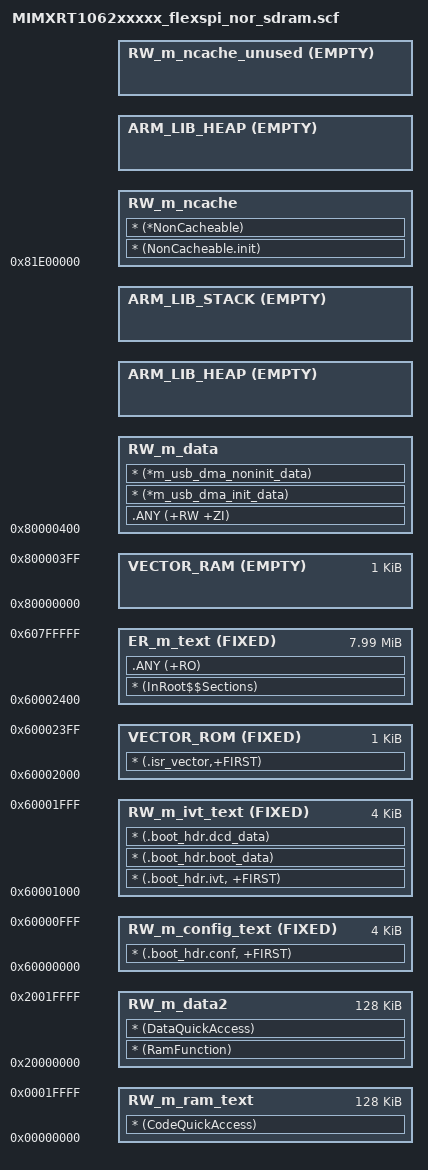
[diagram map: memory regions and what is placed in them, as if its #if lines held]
#!armclang --target=arm-arm-none-eabi -mcpu=cortex-m7 -E -x c
/*
** ###################################################################
**     Processors:          MIMXRT1062CVJ5A
**                          MIMXRT1062CVL5A
**                          MIMXRT1062DVJ6A
**                          MIMXRT1062DVL6A
**                          MIMXRT1062DVN6B
**                          MIMXRT1062XVN5B
**
**     Compiler:            Keil ARM C/C++ Compiler
**     Reference manual:    IMXRT1060RM Rev.3, 07/2021 | IMXRT106XSRM Rev.0
**     Version:             rev. 0.2, 2022-03-25
**     Build:               b220401
**
**     Abstract:
**         Linker file for the Keil ARM C/C++ Compiler
**
**     Copyright 2016 Freescale Semiconductor, Inc.
**     Copyright 2016-2022 NXP
**     All rights reserved.
**
**     SPDX-License-Identifier: BSD-3-Clause
**
**     http:                 www.nxp.com
**     mail:                 support@nxp.com
**
** ###################################################################
*/

#if (defined(__ram_vector_table__))
  #define __ram_vector_table_size__    0x00000400
#else
  #define __ram_vector_table_size__    0x00000000
#endif

#define m_flash_config_start           0x60000000
#define m_flash_config_size            0x00001000

#define m_ivt_start                    0x60001000
#define m_ivt_size                     0x00001000

#define m_interrupts_start             0x60002000
#define m_interrupts_size              0x00000400

#define m_text_start                   0x60002400
#define m_text_size                    0x007FDC00

#define m_qacode_start                 0x00000000
#define m_qacode_size                  0x00020000

#define m_interrupts_ram_start         0x80000000
#define m_interrupts_ram_size          __ram_vector_table_size__

#define m_data_start                   (m_interrupts_ram_start + m_interrupts_ram_size)
#define m_data_size                    (0x01E00000 - m_interrupts_ram_size)

#define m_ncache_start                 0x81E00000
#define m_ncache_size                  0x00200000

#define m_data2_start                  0x20000000
#define m_data2_size                   0x00020000

#define m_data3_start                  0x20200000
#define m_data3_size                   0x000C0000

/* Sizes */
#if (defined(__stack_size__))
  #define Stack_Size                   __stack_size__
#else
  #define Stack_Size                   0x0400
#endif

#if (defined(__heap_size__))
  #define Heap_Size                    __heap_size__
#else
  #define Heap_Size                    0x0400
#endif

#if defined(XIP_BOOT_HEADER_ENABLE) && (XIP_BOOT_HEADER_ENABLE == 1)
LR_m_text m_flash_config_start m_text_start+m_text_size-m_flash_config_start {   ; load region size_region
  RW_m_config_text m_flash_config_start FIXED m_flash_config_size { ; load address = execution address
    * (.boot_hdr.conf, +FIRST)
  }

  RW_m_ivt_text m_ivt_start FIXED m_ivt_size { ; load address = execution address
    * (.boot_hdr.ivt, +FIRST)
    * (.boot_hdr.boot_data)
    * (.boot_hdr.dcd_data)
  }
#else
LR_m_text m_interrupts_start m_text_start+m_text_size-m_interrupts_start {   ; load region size_region
#endif
  VECTOR_ROM m_interrupts_start FIXED m_interrupts_size { ; load address = execution address
    * (.isr_vector,+FIRST)
  }
  ER_m_text m_text_start FIXED m_text_size { ; load address = execution address
    * (InRoot$$Sections)
    .ANY (+RO)
  }
#if (defined(__ram_vector_table__))
  VECTOR_RAM m_interrupts_ram_start EMPTY m_interrupts_ram_size {
  }
#else
  VECTOR_RAM m_interrupts_start EMPTY 0 {
  }
#endif
  RW_m_data2 m_data2_start m_data2_size {
    * (RamFunction)
    * (DataQuickAccess)
  }
#if (defined(__heap_noncacheable__))
  RW_m_data m_data_start m_data_size-Stack_Size { ; RW data
#else
  RW_m_data m_data_start m_data_size-Stack_Size-Heap_Size { ; RW data
#endif
    .ANY (+RW +ZI)
    * (*m_usb_dma_init_data)
    * (*m_usb_dma_noninit_data)
  }
#if (!defined(__heap_noncacheable__))
  ARM_LIB_HEAP +0 EMPTY Heap_Size {    ; Heap region growing up
  }
#endif
  ARM_LIB_STACK m_data_start+m_data_size EMPTY -Stack_Size { ; Stack region growing down
  }
  RW_m_ram_text m_qacode_start m_qacode_size { ;
    * (CodeQuickAccess)
  }
#if (defined(__heap_noncacheable__))
  RW_m_ncache m_ncache_start m_ncache_size - Heap_Size { ; ncache RW data
#else
  RW_m_ncache m_ncache_start m_ncache_size { ; ncache RW data
#endif
    * (NonCacheable.init)
    * (*NonCacheable)
  }
#if (defined(__heap_noncacheable__))
  ARM_LIB_HEAP +0 EMPTY Heap_Size {    ; Heap region growing up
  }
  RW_m_ncache_unused +0 EMPTY m_ncache_size-ImageLength(RW_m_ncache)-Heap_Size { ; Empty region added for MPU configuration
#else
  RW_m_ncache_unused +0 EMPTY m_ncache_size-ImageLength(RW_m_ncache) { ; Empty region added for MPU configuration
#endif
  }
}
